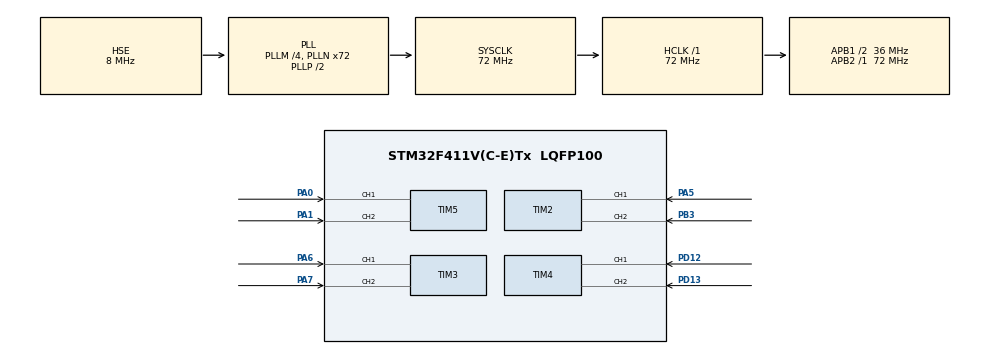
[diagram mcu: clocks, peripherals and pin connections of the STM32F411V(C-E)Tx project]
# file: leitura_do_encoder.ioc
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Mcu.Family=STM32F4
Mcu.Name=STM32F411V(C-E)Tx
Mcu.Package=LQFP100
NVIC.PriorityGroup=NVIC_PRIORITYGROUP_4
PA0-WKUP.Signal=S_TIM5_CH1
PA1.Signal=S_TIM5_CH2
PA13.Mode=Serial_Wire
PA13.Signal=SYS_JTMS-SWDIO
PA14.Mode=Serial_Wire
PA14.Signal=SYS_JTCK-SWCLK
PA5.Signal=S_TIM2_CH1_ETR
PA6.Signal=S_TIM3_CH1
PA7.Signal=S_TIM3_CH2
PB3.Signal=S_TIM2_CH2
PD12.Signal=S_TIM4_CH1
PD13.Signal=S_TIM4_CH2
PH0\ -\ OSC_IN.Mode=HSE-External-Oscillator
PH0\ -\ OSC_IN.Signal=RCC_OSC_IN
PH1\ -\ OSC_OUT.Mode=HSE-External-Oscillator
PH1\ -\ OSC_OUT.Signal=RCC_OSC_OUT
ProjectManager.HeapSize=0x200
ProjectManager.StackSize=0x400
ProjectManager.TargetToolchain=TrueSTUDIO
RCC.48MHZClocksFreq_Value=36000000
RCC.AHBFreq_Value=72000000
RCC.APB1CLKDivider=RCC_HCLK_DIV2
RCC.APB1Freq_Value=36000000
RCC.APB1TimFreq_Value=72000000
RCC.APB2Freq_Value=72000000
RCC.APB2TimFreq_Value=72000000
RCC.CortexFreq_Value=72000000
RCC.HCLKFreq_Value=72000000
RCC.HSE_VALUE=8000000
RCC.HSI_VALUE=16000000
RCC.LSE_VALUE=32768
RCC.PLLM=4
RCC.PLLN=72
RCC.PLLSourceVirtual=RCC_PLLSOURCE_HSE
RCC.SYSCLKFreq_VALUE=72000000
RCC.SYSCLKSource=RCC_SYSCLKSOURCE_PLLCLK
RCC.VCOOutputFreq_Value=144000000
SH.S_TIM2_CH1_ETR.0=TIM2_CH1,Encoder_Interface
SH.S_TIM2_CH2.0=TIM2_CH2,Encoder_Interface
SH.S_TIM3_CH1.0=TIM3_CH1,Encoder_Interface
SH.S_TIM3_CH2.0=TIM3_CH2,Encoder_Interface
SH.S_TIM4_CH1.0=TIM4_CH1,Encoder_Interface
SH.S_TIM4_CH2.0=TIM4_CH2,Encoder_Interface
SH.S_TIM5_CH1.0=TIM5_CH1,Encoder_Interface
SH.S_TIM5_CH2.0=TIM5_CH2,Encoder_Interface
board=leitura_do_encoder

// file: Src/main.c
/**
  ******************************************************************************
  * File Name          : main.c
  * Description        : Main program body
  ******************************************************************************
  ** This notice applies to any and all portions of this file
  * that are not between comment pairs USER CODE BEGIN and
  * USER CODE END. Other portions of this file, whether
  * inserted by the user or by software development tools
  * are owned by their respective copyright owners.
  *
  * COPYRIGHT(c) 2018 STMicroelectronics
  *
  * Redistribution and use in source and binary forms, with or without modification,
  * are permitted provided that the following conditions are met:
  *   1. Redistributions of source code must retain the above copyright notice,
  *      this list of conditions and the following disclaimer.
  *   2. Redistributions in binary form must reproduce the above copyright notice,
  *      this list of conditions and the following disclaimer in the documentation
  *      and/or other materials provided with the distribution.
  *   3. Neither the name of STMicroelectronics nor the names of its contributors
  *      may be used to endorse or promote products derived from this software
  *      without specific prior written permission.
  *
  * THIS SOFTWARE IS PROVIDED BY THE COPYRIGHT HOLDERS AND CONTRIBUTORS "AS IS"
  * AND ANY EXPRESS OR IMPLIED WARRANTIES, INCLUDING, BUT NOT LIMITED TO, THE
  * IMPLIED WARRANTIES OF MERCHANTABILITY AND FITNESS FOR A PARTICULAR PURPOSE ARE
  * DISCLAIMED. IN NO EVENT SHALL THE COPYRIGHT HOLDER OR CONTRIBUTORS BE LIABLE
  * FOR ANY DIRECT, INDIRECT, INCIDENTAL, SPECIAL, EXEMPLARY, OR CONSEQUENTIAL
  * DAMAGES (INCLUDING, BUT NOT LIMITED TO, PROCUREMENT OF SUBSTITUTE GOODS OR
  * SERVICES; LOSS OF USE, DATA, OR PROFITS; OR BUSINESS INTERRUPTION) HOWEVER
  * CAUSED AND ON ANY THEORY OF LIABILITY, WHETHER IN CONTRACT, STRICT LIABILITY,
  * OR TORT (INCLUDING NEGLIGENCE OR OTHERWISE) ARISING IN ANY WAY OUT OF THE USE
  * OF THIS SOFTWARE, EVEN IF ADVISED OF THE POSSIBILITY OF SUCH DAMAGE.
  *
  ******************************************************************************
  */

#include "main.h"
#include "stm32f4xx_hal.h"

TIM_HandleTypeDef htim2;
TIM_HandleTypeDef htim3;
TIM_HandleTypeDef htim4;
TIM_HandleTypeDef htim5;

/* USER CODE BEGIN PV */
/* Private variables ---------------------------------------------------------*/
uint8_t encoderCount;
uint8_t encoderDirection;
char strBuffer[32];
/* USER CODE END PV */

void SystemClock_Config(void);
static void MX_GPIO_Init(void);
static void MX_TIM2_Init(void);
static void MX_TIM5_Init(void);
static void MX_TIM4_Init(void);
static void MX_TIM3_Init(void);

/* USER CODE BEGIN PFP */
/* Private function prototypes -----------------------------------------------*/

/* USER CODE END PFP */

int main(void)
{
  HAL_Init();
  SystemClock_Config();
  MX_GPIO_Init();
  MX_TIM2_Init();
  MX_TIM5_Init();
  MX_TIM4_Init();
  MX_TIM3_Init();
  HAL_TIM_Encoder_Start(&htim2, TIM_CHANNEL_ALL);
  HAL_TIM_Encoder_Start(&htim3, TIM_CHANNEL_ALL);
  HAL_TIM_Encoder_Start(&htim4, TIM_CHANNEL_ALL);
  uint32_t encoderCNT = 1000;
  while (1)
  {
   HAL_Delay(1000);
//   encoderCNT = htim2.Instance->CNT;
   	 encoderCNT = htim3.Instance->CNT;
  }
  /* USER CODE END 3 */

}

/** System Clock Configuration
*/
void SystemClock_Config(void)
{

  RCC_OscInitTypeDef RCC_OscInitStruct;
  RCC_ClkInitTypeDef RCC_ClkInitStruct;

    /**Configure the main internal regulator output voltage
    */
  __HAL_RCC_PWR_CLK_ENABLE();

  __HAL_PWR_VOLTAGESCALING_CONFIG(PWR_REGULATOR_VOLTAGE_SCALE1);

    /**Initializes the CPU, AHB and APB busses clocks
    */
  RCC_OscInitStruct.OscillatorType = RCC_OSCILLATORTYPE_HSE;
  RCC_OscInitStruct.HSEState = RCC_HSE_ON;
  RCC_OscInitStruct.PLL.PLLState = RCC_PLL_ON;
  RCC_OscInitStruct.PLL.PLLSource = RCC_PLLSOURCE_HSE;
  RCC_OscInitStruct.PLL.PLLM = 4;
  RCC_OscInitStruct.PLL.PLLN = 72;
  RCC_OscInitStruct.PLL.PLLP = RCC_PLLP_DIV2;
  RCC_OscInitStruct.PLL.PLLQ = 4;
  if (HAL_RCC_OscConfig(&RCC_OscInitStruct) != HAL_OK)
  {
    _Error_Handler(__FILE__, __LINE__);
  }

    /**Initializes the CPU, AHB and APB busses clocks
    */
  RCC_ClkInitStruct.ClockType = RCC_CLOCKTYPE_HCLK|RCC_CLOCKTYPE_SYSCLK
                              |RCC_CLOCKTYPE_PCLK1|RCC_CLOCKTYPE_PCLK2;
  RCC_ClkInitStruct.SYSCLKSource = RCC_SYSCLKSOURCE_PLLCLK;
  RCC_ClkInitStruct.AHBCLKDivider = RCC_SYSCLK_DIV1;
  RCC_ClkInitStruct.APB1CLKDivider = RCC_HCLK_DIV2;
  RCC_ClkInitStruct.APB2CLKDivider = RCC_HCLK_DIV1;

  if (HAL_RCC_ClockConfig(&RCC_ClkInitStruct, FLASH_LATENCY_2) != HAL_OK)
  {
    _Error_Handler(__FILE__, __LINE__);
  }

    /**Configure the Systick interrupt time
    */
  HAL_SYSTICK_Config(HAL_RCC_GetHCLKFreq()/1000);

    /**Configure the Systick
    */
  HAL_SYSTICK_CLKSourceConfig(SYSTICK_CLKSOURCE_HCLK);

  /* SysTick_IRQn interrupt configuration */
  HAL_NVIC_SetPriority(SysTick_IRQn, 0, 0);
}

/* TIM2 init function */
static void MX_TIM2_Init(void)
{

  TIM_Encoder_InitTypeDef sConfig;
  TIM_MasterConfigTypeDef sMasterConfig;

  htim2.Instance = TIM2;
  htim2.Init.Prescaler = 0;
  htim2.Init.CounterMode = TIM_COUNTERMODE_UP;
  htim2.Init.Period = 0xffff;
  htim2.Init.ClockDivision = TIM_CLOCKDIVISION_DIV1;
  sConfig.EncoderMode = TIM_ENCODERMODE_TI12;
  sConfig.IC1Polarity = TIM_ICPOLARITY_RISING;
  sConfig.IC1Selection = TIM_ICSELECTION_DIRECTTI;
  sConfig.IC1Prescaler = TIM_ICPSC_DIV1;
  sConfig.IC1Filter = 0;
  sConfig.IC2Polarity = TIM_ICPOLARITY_RISING;
  sConfig.IC2Selection = TIM_ICSELECTION_DIRECTTI;
  sConfig.IC2Prescaler = TIM_ICPSC_DIV1;
  sConfig.IC2Filter = 0;
  if (HAL_TIM_Encoder_Init(&htim2, &sConfig) != HAL_OK)
  {
    _Error_Handler(__FILE__, __LINE__);
  }

  sMasterConfig.MasterOutputTrigger = TIM_TRGO_RESET;
  sMasterConfig.MasterSlaveMode = TIM_MASTERSLAVEMODE_DISABLE;
  if (HAL_TIMEx_MasterConfigSynchronization(&htim2, &sMasterConfig) != HAL_OK)
  {
    _Error_Handler(__FILE__, __LINE__);
  }

}

/* TIM3 init function */
static void MX_TIM3_Init(void)
{

  TIM_Encoder_InitTypeDef sConfig;
  TIM_MasterConfigTypeDef sMasterConfig;

  htim3.Instance = TIM3;
  htim3.Init.Prescaler = 0;
  htim3.Init.CounterMode = TIM_COUNTERMODE_UP;
  htim3.Init.Period = 0xffff;
  htim3.Init.ClockDivision = TIM_CLOCKDIVISION_DIV1;
  sConfig.EncoderMode = TIM_ENCODERMODE_TI12;
  sConfig.IC1Polarity = TIM_ICPOLARITY_RISING;
  sConfig.IC1Selection = TIM_ICSELECTION_DIRECTTI;
  sConfig.IC1Prescaler = TIM_ICPSC_DIV1;
  sConfig.IC1Filter = 0;
  sConfig.IC2Polarity = TIM_ICPOLARITY_RISING;
  sConfig.IC2Selection = TIM_ICSELECTION_DIRECTTI;
  sConfig.IC2Prescaler = TIM_ICPSC_DIV1;
  sConfig.IC2Filter = 0;
  if (HAL_TIM_Encoder_Init(&htim3, &sConfig) != HAL_OK)
  {
    _Error_Handler(__FILE__, __LINE__);
  }

  sMasterConfig.MasterOutputTrigger = TIM_TRGO_RESET;
  sMasterConfig.MasterSlaveMode = TIM_MASTERSLAVEMODE_DISABLE;
  if (HAL_TIMEx_MasterConfigSynchronization(&htim3, &sMasterConfig) != HAL_OK)
  {
    _Error_Handler(__FILE__, __LINE__);
  }

}

/* TIM4 init function */
static void MX_TIM4_Init(void)
{

  TIM_Encoder_InitTypeDef sConfig;
  TIM_MasterConfigTypeDef sMasterConfig;

  htim4.Instance = TIM4;
  htim4.Init.Prescaler = 0;
  htim4.Init.CounterMode = TIM_COUNTERMODE_UP;
  htim4.Init.Period = 0;
  htim4.Init.ClockDivision = TIM_CLOCKDIVISION_DIV1;
  sConfig.EncoderMode = TIM_ENCODERMODE_TI1;
  sConfig.IC1Polarity = TIM_ICPOLARITY_RISING;
  sConfig.IC1Selection = TIM_ICSELECTION_DIRECTTI;
  sConfig.IC1Prescaler = TIM_ICPSC_DIV1;
  sConfig.IC1Filter = 0;
  sConfig.IC2Polarity = TIM_ICPOLARITY_RISING;
  sConfig.IC2Selection = TIM_ICSELECTION_DIRECTTI;
  sConfig.IC2Prescaler = TIM_ICPSC_DIV1;
  sConfig.IC2Filter = 0;
  if (HAL_TIM_Encoder_Init(&htim4, &sConfig) != HAL_OK)
  {
    _Error_Handler(__FILE__, __LINE__);
  }

  sMasterConfig.MasterOutputTrigger = TIM_TRGO_RESET;
  sMasterConfig.MasterSlaveMode = TIM_MASTERSLAVEMODE_DISABLE;
  if (HAL_TIMEx_MasterConfigSynchronization(&htim4, &sMasterConfig) != HAL_OK)
  {
    _Error_Handler(__FILE__, __LINE__);
  }

}

/* TIM5 init function */
static void MX_TIM5_Init(void)
{

  TIM_Encoder_InitTypeDef sConfig;
  TIM_MasterConfigTypeDef sMasterConfig;

  htim5.Instance = TIM5;
  htim5.Init.Prescaler = 0;
  htim5.Init.CounterMode = TIM_COUNTERMODE_UP;
  htim5.Init.Period = 0;
  htim5.Init.ClockDivision = TIM_CLOCKDIVISION_DIV1;
  sConfig.EncoderMode = TIM_ENCODERMODE_TI1;
  sConfig.IC1Polarity = TIM_ICPOLARITY_RISING;
  sConfig.IC1Selection = TIM_ICSELECTION_DIRECTTI;
  sConfig.IC1Prescaler = TIM_ICPSC_DIV1;
  sConfig.IC1Filter = 0;
  sConfig.IC2Polarity = TIM_ICPOLARITY_RISING;
  sConfig.IC2Selection = TIM_ICSELECTION_DIRECTTI;
  sConfig.IC2Prescaler = TIM_ICPSC_DIV1;
  sConfig.IC2Filter = 0;
  if (HAL_TIM_Encoder_Init(&htim5, &sConfig) != HAL_OK)
  {
    _Error_Handler(__FILE__, __LINE__);
  }

  sMasterConfig.MasterOutputTrigger = TIM_TRGO_RESET;
  sMasterConfig.MasterSlaveMode = TIM_MASTERSLAVEMODE_DISABLE;
  if (HAL_TIMEx_MasterConfigSynchronization(&htim5, &sMasterConfig) != HAL_OK)
  {
    _Error_Handler(__FILE__, __LINE__);
  }

}

/** Configure pins as
        * Analog
        * Input
        * Output
        * EVENT_OUT
        * EXTI
*/
static void MX_GPIO_Init(void)
{

  /* GPIO Ports Clock Enable */
  __HAL_RCC_GPIOH_CLK_ENABLE();
  __HAL_RCC_GPIOA_CLK_ENABLE();
  __HAL_RCC_GPIOD_CLK_ENABLE();
  __HAL_RCC_GPIOB_CLK_ENABLE();

}

void _Error_Handler(char * file, int line)
{
  while(1)
  {
  }
}

/************************ (C) COPYRIGHT STMicroelectronics *****END OF FILE****/
